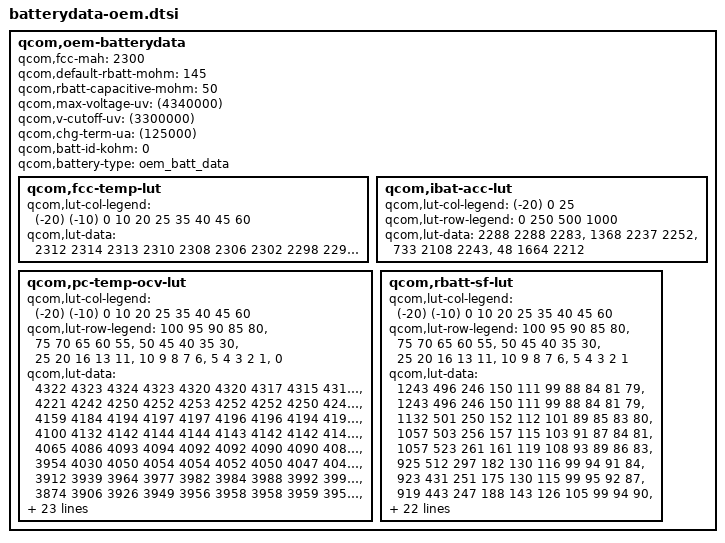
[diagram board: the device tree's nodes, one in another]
/* Copyright (c) 2013-2014, The Linux Foundation. All rights reserved.
 *
 * This program is free software; you can redistribute it and/or modify
 * it under the terms of the GNU General Public License version 2 and
 * only version 2 as published by the Free Software Foundation.
 *
 * This program is distributed in the hope that it will be useful,
 * but WITHOUT ANY WARRANTY; without even the implied warranty of
 * MERCHANTABILITY or FITNESS FOR A PARTICULAR PURPOSE.  See the
 * GNU General Public License for more details.
 */
/*
 * This software is contributed or developed by KYOCERA Corporation.
 * (C) 2015 KYOCERA Corporation
 */

qcom,oem-batterydata {
	qcom,fcc-mah = <2300>;
	qcom,default-rbatt-mohm = <145>;
	qcom,rbatt-capacitive-mohm = <50>;
	qcom,max-voltage-uv = <(4340000)>;
	qcom,v-cutoff-uv = <(3300000)>;
	qcom,chg-term-ua = <(125000)>;
	qcom,batt-id-kohm = <0>;
	qcom,battery-type = "oem_batt_data";

	qcom,fcc-temp-lut {
		qcom,lut-col-legend = <(-20) (-10) 0 10 20 25 35 40 45 60>;
		qcom,lut-data = <2312 2314 2313 2310 2308 2306 2302 2298 2294 2278>;
	};

	qcom,ibat-acc-lut {
		qcom,lut-col-legend = <(-20) 0 25>;
		qcom,lut-row-legend = <0 250 500 1000>;
		qcom,lut-data = <2288 2288 2283>,
				<1368 2237 2252>,
				<733 2108 2243>,
				<48 1664 2212>;
	};

	qcom,pc-temp-ocv-lut {
		qcom,lut-col-legend = <(-20) (-10) 0 10 20 25 35 40 45 60>;
		qcom,lut-row-legend = <100 95 90 85 80>,
				<75 70 65 60 55>,
				<50 45 40 35 30>,
				<25 20 16 13 11>,
				<10 9 8 7 6>,
				<5 4 3 2 1>,
				<0>;
		qcom,lut-data = <4322 4323 4324 4323 4320 4320 4317 4315 4313 4308>,
				<4221 4242 4250 4252 4253 4252 4252 4250 4249 4246>,
				<4159 4184 4194 4197 4197 4196 4196 4194 4194 4190>,
				<4100 4132 4142 4144 4144 4143 4142 4142 4140 4138>,
				<4065 4086 4093 4094 4092 4092 4090 4090 4089 4086>,
				<3954 4030 4050 4054 4054 4052 4050 4047 4044 4040>,
				<3912 3939 3964 3977 3982 3984 3988 3992 3996 3996>,
				<3874 3906 3926 3949 3956 3958 3958 3959 3958 3956>,
				<3837 3876 3892 3906 3919 3922 3923 3923 3924 3922>,
				<3818 3844 3858 3863 3868 3870 3874 3874 3874 3873>,
				<3807 3816 3830 3834 3836 3836 3836 3837 3837 3837>,
				<3796 3800 3808 3812 3814 3814 3814 3814 3814 3815>,
				<3786 3790 3791 3794 3796 3796 3797 3797 3797 3796>,
				<3774 3780 3782 3782 3782 3782 3782 3782 3782 3782>,
				<3760 3770 3776 3775 3774 3772 3770 3769 3768 3765>,
				<3747 3756 3766 3768 3766 3764 3758 3754 3751 3742>,
				<3732 3736 3748 3753 3749 3746 3739 3736 3732 3722>,
				<3718 3720 3722 3724 3722 3720 3714 3711 3708 3697>,
				<3706 3710 3705 3702 3698 3695 3690 3686 3684 3676>,
				<3696 3702 3698 3695 3692 3690 3684 3682 3679 3670>,
				<3690 3698 3696 3694 3690 3688 3684 3680 3678 3669>,
				<3684 3696 3694 3692 3690 3688 3682 3680 3677 3668>,
				<3676 3692 3691 3691 3688 3686 3682 3678 3676 3667>,
				<3665 3687 3690 3689 3687 3685 3680 3678 3675 3666>,
				<3652 3681 3686 3686 3684 3682 3677 3674 3670 3662>,
				<3632 3670 3680 3680 3675 3672 3664 3660 3656 3646>,
				<3602 3644 3653 3648 3641 3636 3627 3623 3618 3608>,
				<3558 3599 3600 3592 3584 3577 3568 3564 3558 3552>,
				<3493 3531 3523 3512 3504 3497 3488 3484 3479 3476>,
				<3388 3420 3406 3394 3388 3379 3365 3362 3356 3362>,
				<3000 3000 3000 3000 3000 3000 3000 3000 3000 3000>;
	};

	qcom,rbatt-sf-lut {
		qcom,lut-col-legend = <(-20) (-10) 0 10 20 25 35 40 45 60>;
		qcom,lut-row-legend = <100 95 90 85 80>,
				<75 70 65 60 55>,
				<50 45 40 35 30>,
				<25 20 16 13 11>,
				<10 9 8 7 6>,
				<5 4 3 2 1>;
		qcom,lut-data = <1243 496 246 150 111 99 88 84 81 79>,
				<1243 496 246 150 111 99 88 84 81 79>,
				<1132 501 250 152 112 101 89 85 83 80>,
				<1057 503 256 157 115 103 91 87 84 81>,
				<1057 523 261 161 119 108 93 89 86 83>,
				<925 512 297 182 130 116 99 94 91 84>,
				<923 431 251 175 130 115 99 95 92 87>,
				<919 443 247 188 143 126 105 99 94 90>,
				<913 446 237 168 146 134 114 108 103 95>,
				<944 437 228 149 119 112 102 97 94 88>,
				<994 434 225 143 109 101 88 85 82 81>,
				<1047 455 225 145 110 101 88 86 84 82>,
				<1103 492 225 146 111 102 91 89 87 86>,
				<1161 539 237 146 113 105 93 92 90 88>,
				<1220 594 261 154 118 107 93 90 90 87>,
				<1286 652 289 167 122 111 92 87 85 82>,
				<1363 719 318 177 122 108 90 87 86 82>,
				<1448 781 332 176 120 107 92 88 86 82>,
				<1514 837 348 174 117 105 90 86 84 81>,
				<1484 830 349 173 117 105 90 88 86 83>,
				<1448 805 343 171 117 106 92 88 86 84>,
				<1504 834 357 174 119 108 93 90 88 86>,
				<1563 870 375 182 122 110 96 92 90 87>,
				<1685 916 400 189 128 114 99 95 92 90>,
				<1892 966 423 202 133 120 103 99 95 93>,
				<2132 1017 454 216 138 121 102 97 95 90>,
				<2458 1077 469 209 131 116 99 93 90 87>,
				<2942 1155 497 221 135 119 101 95 92 89>,
				<3712 1271 566 248 148 131 112 108 106 101>,
				<5320 1692 679 302 186 171 150 145 202 125>;
	};
};
